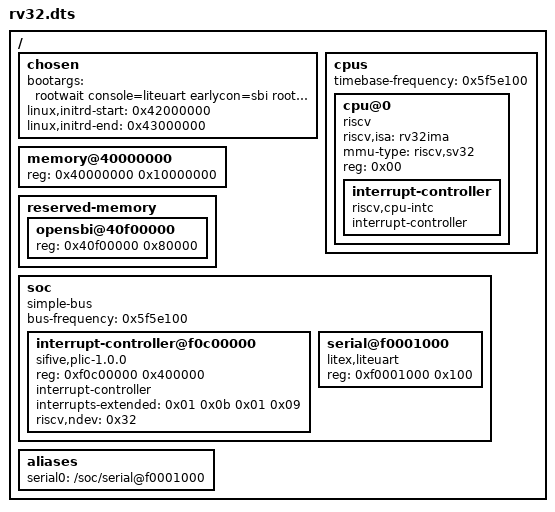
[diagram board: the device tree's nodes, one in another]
/dts-v1/;

/ {
	#address-cells = <0x01>;
	#size-cells = <0x01>;

	chosen {
		bootargs = "rootwait console=liteuart earlycon=sbi root=/dev/ram0 init=/sbin/init swiotlb=0032";
		linux,initrd-start = <0x42000000>;
		linux,initrd-end = <0x43000000>;
	};

	cpus {
		#address-cells = <0x01>;
		#size-cells = <0x00>;
		timebase-frequency = <0x5f5e100>;

		cpu@0 {
			device_type = "cpu";
			compatible = "riscv";
			riscv,isa = "rv32ima";
			mmu-type = "riscv,sv32";
			reg = <0x00>;
			status = "okay";

			interrupt-controller {
				#interrupt-cells = <0x01>;
				interrupt-controller;
				compatible = "riscv,cpu-intc";
				phandle = <0x01>;
			};
		};
	};

	memory@40000000 {
		device_type = "memory";
		reg = <0x40000000 0x10000000>;
	};

	reserved-memory {
		#address-cells = <0x01>;
		#size-cells = <0x01>;
		ranges;

		opensbi@40f00000 {
			reg = <0x40f00000 0x80000>;
		};
	};

	soc {
		#address-cells = <0x01>;
		#size-cells = <0x01>;
		bus-frequency = <0x5f5e100>;
		compatible = "simple-bus";
		ranges;

		interrupt-controller@f0c00000 {
			compatible = "sifive,plic-1.0.0\0sifive,fu540-c000-plic";
			reg = <0xf0c00000 0x400000>;
			#interrupt-cells = <0x01>;
			interrupt-controller;
			interrupts-extended = <0x01 0x0b 0x01 0x09>;
			riscv,ndev = <0x32>;
			phandle = <0x02>;
		};

		serial@f0001000 {
			device_type = "serial";
			compatible = "litex,liteuart";
			reg = <0xf0001000 0x100>;
			status = "okay";
		};
	};

	aliases {
		serial0 = "/soc/serial@f0001000";
	};
};
